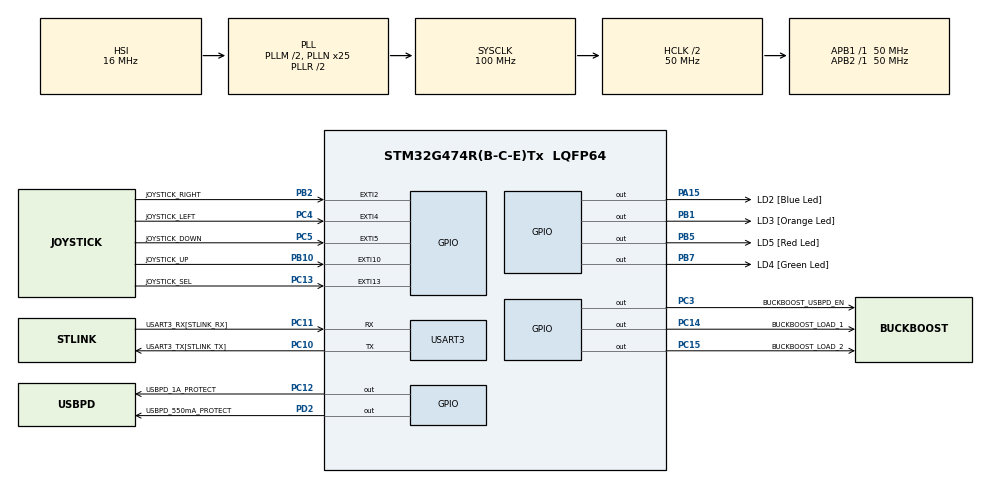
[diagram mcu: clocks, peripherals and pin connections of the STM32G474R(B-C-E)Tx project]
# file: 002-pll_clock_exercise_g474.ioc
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Mcu.Family=STM32G4
Mcu.Name=STM32G474R(B-C-E)Tx
Mcu.Package=LQFP64
NVIC.EXTI15_10_IRQn=true\:0\:0\:false\:false\:true\:true\:true
NVIC.EXTI2_IRQn=true\:0\:0\:false\:false\:true\:true\:true
NVIC.EXTI4_IRQn=true\:0\:0\:false\:false\:true\:true\:true
NVIC.EXTI9_5_IRQn=true\:0\:0\:false\:false\:true\:true\:true
NVIC.PriorityGroup=NVIC_PRIORITYGROUP_4
NVIC.USART3_IRQn=true\:0\:0\:false\:false\:true\:true\:true
PA0.GPIO_Label=BUCK_GREEN_SENSE
PA0.Signal=COMP3_INP
PA1.GPIO_Label=BUCKBOOST_VIN
PA1.Signal=ADC1_IN2
PA10.Signal=UCPD1_DBCC2
PA11.Signal=USB_DM
PA12.Signal=USB_DP
PA13.Mode=Serial_Wire
PA13.Signal=SYS_JTMS-SWDIO
PA14.Mode=Serial_Wire
PA14.Signal=SYS_JTCK-SWCLK
PA15.GPIO_Label=LD2 [Blue Led]
PA15.Signal=GPIO_Output
PA2.GPIO_Label=BUCKBOOST_I_IN_AVG
PA2.Signal=ADC1_IN3
PA3.GPIO_Label=BUCKBOOST_VOUT
PA3.Signal=ADC1_IN4
PA7.GPIO_Label=BUCK_RED_SENSE
PA7.Signal=COMP2_INP
PA8.GPIO_Label=BUCK_BLUE_DRIVE
PA8.Signal=HRTIM1_CHA1
PA9.Signal=UCPD1_DBCC1
PB0.GPIO_Label=BUCK_BLUE_SENSE
PB0.Signal=COMP4_INP
PB1.GPIO_Label=LD3 [Orange Led]
PB1.Signal=GPIO_Output
PB10.GPIO_Label=JOYSTICK_UP
PB10.GPIO_PuPd=GPIO_PULLUP
PB10.Signal=GPXTI10
PB11.GPIO_Label=BUCKBOOST_I_IN_SENSE
PB11.Signal=COMP6_INP
PB12.GPIO_Label=BUCKBOOST_P1_DRIVE
PB12.Signal=HRTIM1_CHC1
PB13.GPIO_Label=BUCKBOOST_N1_DRIVE
PB13.Signal=HRTIM1_CHC2
PB14.GPIO_Label=BUCKBOOST_N2_DRIVE
PB14.Signal=HRTIM1_CHD1
PB15.GPIO_Label=BUCKBOOST_P2_DRIVE
PB15.Signal=HRTIM1_CHD2
PB2.GPIO_Label=JOYSTICK_RIGHT
PB2.GPIO_PuPd=GPIO_PULLUP
PB2.Signal=GPXTI2
PB3.Signal=SYS_JTDO-SWO
PB4.Signal=UCPD1_CC2
PB5.GPIO_Label=LD5 [Red Led]
PB5.Signal=GPIO_Output
PB6.Signal=UCPD1_CC1
PB7.GPIO_Label=LD4 [Green Led]
PB7.Signal=GPIO_Output
PC10.GPIO_Label=USART3_TX[STLINK_TX]
PC10.GPIO_Speed=GPIO_SPEED_FREQ_MEDIUM
PC10.Mode=Asynchronous
PC10.Signal=USART3_TX
PC11.GPIO_Label=USART3_RX[STLINK_RX]
PC11.GPIO_Speed=GPIO_SPEED_FREQ_MEDIUM
PC11.Mode=Asynchronous
PC11.Signal=USART3_RX
PC12.GPIO_Label=USBPD_1A_PROTECT
PC12.Signal=GPIO_Output
PC13.GPIO_Label=JOYSTICK_SEL
PC13.GPIO_PuPd=GPIO_PULLUP
PC13.Signal=GPXTI13
PC14-OSC32_IN.GPIO_Label=BUCKBOOST_LOAD_1
PC14-OSC32_IN.Signal=GPIO_Output
PC15-OSC32_OUT.GPIO_Label=BUCKBOOST_LOAD_2
PC15-OSC32_OUT.Signal=GPIO_Output
PC2.GPIO_Label=USBPD_VIN
PC2.Signal=ADC1_IN8
PC3.GPIO_Label=BUCKBOOST_USBPD_EN
PC3.Signal=GPIO_Output
PC4.GPIO_Label=JOYSTICK_LEFT
PC4.GPIO_PuPd=GPIO_PULLUP
PC4.Signal=GPXTI4
PC5.GPIO_Label=JOYSTICK_DOWN
PC5.GPIO_PuPd=GPIO_PULLUP
PC5.Signal=GPXTI5
PC6.GPIO_Label=BUCK_RED_DRIVE
PC6.Signal=HRTIM1_CHF1
PC7.GPIO_Label=RC_TP4
PC7.Signal=HRTIM1_CHF2
PC8.GPIO_Label=BUCK_GREEN_DRIVE
PC8.Signal=HRTIM1_CHE1
PD2.GPIO_Label=USBPD_550mA_PROTECT
PD2.Signal=GPIO_Output
PF0-OSC_IN.Mode=HSE-External-Clock-Source
PF0-OSC_IN.Signal=RCC_OSC_IN
ProjectManager.HeapSize=0x200
ProjectManager.StackSize=0x400
ProjectManager.TargetToolchain=STM32CubeIDE
RCC.ADC12Freq_Value=100000000
RCC.ADC345Freq_Value=100000000
RCC.AHBCLKDivider=RCC_SYSCLK_DIV2
RCC.AHBFreq_Value=50000000
RCC.APB1Freq_Value=50000000
RCC.APB1TimFreq_Value=50000000
RCC.APB2Freq_Value=50000000
RCC.APB2TimFreq_Value=50000000
RCC.CK48CLockSelection=RCC_USBCLKSOURCE_HSI48
RCC.CortexFreq_Value=50000000
RCC.EXTERNAL_CLOCK_VALUE=12288000
RCC.HCLKFreq_Value=50000000
RCC.HSE_VALUE=8000000
RCC.HSI48_VALUE=48000000
RCC.HSI_VALUE=16000000
RCC.LSE_VALUE=32768
RCC.PLLM=RCC_PLLM_DIV2
RCC.PLLN=25
RCC.PLLP=RCC_PLLP_DIV8
RCC.PLLQ=RCC_PLLQ_DIV8
RCC.SYSCLKFreq_VALUE=100000000
RCC.SYSCLKSource=RCC_SYSCLKSOURCE_PLLCLK
RCC.USBFreq_Value=48000000
RCC.VCOOutputFreq_Value=200000000
USART3.VirtualMode-Asynchronous=VM_ASYNC
VP_SYS_VS_DBSignals.Mode=DisableDeadBatterySignals
board=B-G474E-DPOW1

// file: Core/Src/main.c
/* USER CODE BEGIN Header */
/**
  ******************************************************************************
  * @file           : main.c
  * @brief          : Main program body
  ******************************************************************************
  * @attention
  *
  * <h2><center>&copy; Copyright (c) 2020 STMicroelectronics.
  * All rights reserved.</center></h2>
  *
  * This software component is licensed by ST under BSD 3-Clause license,
  * the "License"; You may not use this file except in compliance with the
  * License. You may obtain a copy of the License at:
  *                        opensource.org/licenses/BSD-3-Clause
  *
  ******************************************************************************
  */
/* USER CODE END Header */

#include "main.h"
#include <stdio.h>
#include <string.h>

UART_HandleTypeDef huart3;

void SystemClock_Config(void);
static void MX_GPIO_Init(void);
static void MX_USART3_UART_Init(void);

int main(void)
{
  /* USER CODE BEGIN 1 */
	char msg[30] = {0};

  /* USER CODE END 1 */

  /* MCU Configuration--------------------------------------------------------*/

  /* Reset of all peripherals, Initializes the Flash interface and the Systick. */
  HAL_Init();

  /* Configure the system clock */
  SystemClock_Config();

  /* Initialize all configured peripherals */
  MX_GPIO_Init();
  MX_USART3_UART_Init();
  /* USER CODE BEGIN 2 */
  memset(msg, 0, sizeof(msg));
  sprintf(msg, "SYSCLK w/ PLL: %ld", HAL_RCC_GetSysClockFreq());
  HAL_UART_Transmit(&huart3, (uint8_t*)msg, strlen(msg), HAL_MAX_DELAY);

  /* USER CODE END 2 */

  /* Infinite loop */
  while (1)
  {

  }
}

void SystemClock_Config(void)
{
  RCC_OscInitTypeDef RCC_OscInitStruct = {0};
  RCC_ClkInitTypeDef RCC_ClkInitStruct = {0};
  RCC_PeriphCLKInitTypeDef PeriphClkInit = {0};

  /** Configure the main internal regulator output voltage
  */
  HAL_PWREx_ControlVoltageScaling(PWR_REGULATOR_VOLTAGE_SCALE1);
  /** Initializes the CPU, AHB and APB busses clocks
  */
  RCC_OscInitStruct.OscillatorType = RCC_OSCILLATORTYPE_HSI;
  RCC_OscInitStruct.HSIState = RCC_HSI_ON;
  RCC_OscInitStruct.HSICalibrationValue = RCC_HSICALIBRATION_DEFAULT;
  RCC_OscInitStruct.PLL.PLLState = RCC_PLL_ON;
  RCC_OscInitStruct.PLL.PLLSource = RCC_PLLSOURCE_HSI;
  RCC_OscInitStruct.PLL.PLLM = RCC_PLLM_DIV2;
  RCC_OscInitStruct.PLL.PLLN = 25;
  RCC_OscInitStruct.PLL.PLLP = RCC_PLLP_DIV8;
  RCC_OscInitStruct.PLL.PLLQ = RCC_PLLQ_DIV8;
  RCC_OscInitStruct.PLL.PLLR = RCC_PLLR_DIV2;
  if (HAL_RCC_OscConfig(&RCC_OscInitStruct) != HAL_OK)
  {
    Error_Handler();
  }
  /** Initializes the CPU, AHB and APB busses clocks
  */
  RCC_ClkInitStruct.ClockType = RCC_CLOCKTYPE_HCLK|RCC_CLOCKTYPE_SYSCLK
                              |RCC_CLOCKTYPE_PCLK1|RCC_CLOCKTYPE_PCLK2;
  RCC_ClkInitStruct.SYSCLKSource = RCC_SYSCLKSOURCE_PLLCLK;
  RCC_ClkInitStruct.AHBCLKDivider = RCC_SYSCLK_DIV2;
  RCC_ClkInitStruct.APB1CLKDivider = RCC_HCLK_DIV1;
  RCC_ClkInitStruct.APB2CLKDivider = RCC_HCLK_DIV1;

  if (HAL_RCC_ClockConfig(&RCC_ClkInitStruct, FLASH_LATENCY_2) != HAL_OK)
  {
    Error_Handler();
  }
  /** Initializes the peripherals clocks
  */
  PeriphClkInit.PeriphClockSelection = RCC_PERIPHCLK_USART3;
  PeriphClkInit.Usart3ClockSelection = RCC_USART3CLKSOURCE_PCLK1;
  if (HAL_RCCEx_PeriphCLKConfig(&PeriphClkInit) != HAL_OK)
  {
    Error_Handler();
  }
}

static void MX_USART3_UART_Init(void)
{

  huart3.Instance = USART3;
  huart3.Init.BaudRate = 115200;
  huart3.Init.WordLength = UART_WORDLENGTH_8B;
  huart3.Init.StopBits = UART_STOPBITS_1;
  huart3.Init.Parity = UART_PARITY_NONE;
  huart3.Init.Mode = UART_MODE_TX_RX;
  huart3.Init.HwFlowCtl = UART_HWCONTROL_NONE;
  huart3.Init.OverSampling = UART_OVERSAMPLING_16;
  huart3.Init.OneBitSampling = UART_ONE_BIT_SAMPLE_DISABLE;
  huart3.Init.ClockPrescaler = UART_PRESCALER_DIV1;
  huart3.AdvancedInit.AdvFeatureInit = UART_ADVFEATURE_NO_INIT;
  if (HAL_UART_Init(&huart3) != HAL_OK)
  {
    Error_Handler();
  }
  if (HAL_UARTEx_SetTxFifoThreshold(&huart3, UART_TXFIFO_THRESHOLD_1_8) != HAL_OK)
  {
    Error_Handler();
  }
  if (HAL_UARTEx_SetRxFifoThreshold(&huart3, UART_RXFIFO_THRESHOLD_1_8) != HAL_OK)
  {
    Error_Handler();
  }
  if (HAL_UARTEx_DisableFifoMode(&huart3) != HAL_OK)
  {
    Error_Handler();
  }

}

static void MX_GPIO_Init(void)
{
  GPIO_InitTypeDef GPIO_InitStruct = {0};

  /* GPIO Ports Clock Enable */
  __HAL_RCC_GPIOC_CLK_ENABLE();
  __HAL_RCC_GPIOF_CLK_ENABLE();
  __HAL_RCC_GPIOA_CLK_ENABLE();
  __HAL_RCC_GPIOB_CLK_ENABLE();
  __HAL_RCC_GPIOD_CLK_ENABLE();

  /*Configure GPIO pin Output Level */
  HAL_GPIO_WritePin(GPIOC, BUCKBOOST_LOAD_1_Pin|BUCKBOOST_LOAD_2_Pin|BUCKBOOST_USBPD_EN_Pin|USBPD_1A_PROTECT_Pin, GPIO_PIN_RESET);

  /*Configure GPIO pin Output Level */
  HAL_GPIO_WritePin(GPIOB, LD3_Pin|LD5_Pin|LD4_Pin, GPIO_PIN_RESET);

  /*Configure GPIO pin Output Level */
  HAL_GPIO_WritePin(LD2_GPIO_Port, LD2_Pin, GPIO_PIN_RESET);

  /*Configure GPIO pin Output Level */
  HAL_GPIO_WritePin(USBPD_550mA_PROTECT_GPIO_Port, USBPD_550mA_PROTECT_Pin, GPIO_PIN_RESET);

  /*Configure GPIO pins : JOYSTICK_SEL_Pin JOYSTICK_LEFT_Pin JOYSTICK_DOWN_Pin */
  GPIO_InitStruct.Pin = JOYSTICK_SEL_Pin|JOYSTICK_LEFT_Pin|JOYSTICK_DOWN_Pin;
  GPIO_InitStruct.Mode = GPIO_MODE_IT_RISING;
  GPIO_InitStruct.Pull = GPIO_PULLUP;
  HAL_GPIO_Init(GPIOC, &GPIO_InitStruct);

  /*Configure GPIO pins : BUCKBOOST_LOAD_1_Pin BUCKBOOST_LOAD_2_Pin BUCKBOOST_USBPD_EN_Pin USBPD_1A_PROTECT_Pin */
  GPIO_InitStruct.Pin = BUCKBOOST_LOAD_1_Pin|BUCKBOOST_LOAD_2_Pin|BUCKBOOST_USBPD_EN_Pin|USBPD_1A_PROTECT_Pin;
  GPIO_InitStruct.Mode = GPIO_MODE_OUTPUT_PP;
  GPIO_InitStruct.Pull = GPIO_NOPULL;
  GPIO_InitStruct.Speed = GPIO_SPEED_FREQ_LOW;
  HAL_GPIO_Init(GPIOC, &GPIO_InitStruct);

  /*Configure GPIO pin : USBPD_VIN_Pin */
  GPIO_InitStruct.Pin = USBPD_VIN_Pin;
  GPIO_InitStruct.Mode = GPIO_MODE_ANALOG;
  GPIO_InitStruct.Pull = GPIO_NOPULL;
  HAL_GPIO_Init(USBPD_VIN_GPIO_Port, &GPIO_InitStruct);

  /*Configure GPIO pins : BUCK_GREEN_SENSE_Pin BUCKBOOST_VIN_Pin BUCKBOOST_I_IN_AVG_Pin BUCKBOOST_VOUT_Pin
                           BUCK_RED_SENSE_Pin */
  GPIO_InitStruct.Pin = BUCK_GREEN_SENSE_Pin|BUCKBOOST_VIN_Pin|BUCKBOOST_I_IN_AVG_Pin|BUCKBOOST_VOUT_Pin
                          |BUCK_RED_SENSE_Pin;
  GPIO_InitStruct.Mode = GPIO_MODE_ANALOG;
  GPIO_InitStruct.Pull = GPIO_NOPULL;
  HAL_GPIO_Init(GPIOA, &GPIO_InitStruct);

  /*Configure GPIO pins : BUCK_BLUE_SENSE_Pin BUCKBOOST_I_IN_SENSE_Pin */
  GPIO_InitStruct.Pin = BUCK_BLUE_SENSE_Pin|BUCKBOOST_I_IN_SENSE_Pin;
  GPIO_InitStruct.Mode = GPIO_MODE_ANALOG;
  GPIO_InitStruct.Pull = GPIO_NOPULL;
  HAL_GPIO_Init(GPIOB, &GPIO_InitStruct);

  /*Configure GPIO pins : LD3_Pin LD5_Pin LD4_Pin */
  GPIO_InitStruct.Pin = LD3_Pin|LD5_Pin|LD4_Pin;
  GPIO_InitStruct.Mode = GPIO_MODE_OUTPUT_PP;
  GPIO_InitStruct.Pull = GPIO_NOPULL;
  GPIO_InitStruct.Speed = GPIO_SPEED_FREQ_LOW;
  HAL_GPIO_Init(GPIOB, &GPIO_InitStruct);

  /*Configure GPIO pins : JOYSTICK_RIGHT_Pin JOYSTICK_UP_Pin */
  GPIO_InitStruct.Pin = JOYSTICK_RIGHT_Pin|JOYSTICK_UP_Pin;
  GPIO_InitStruct.Mode = GPIO_MODE_IT_RISING;
  GPIO_InitStruct.Pull = GPIO_PULLUP;
  HAL_GPIO_Init(GPIOB, &GPIO_InitStruct);

  /*Configure GPIO pins : BUCKBOOST_P1_DRIVE_Pin BUCKBOOST_N1_DRIVE_Pin BUCKBOOST_N2_DRIVE_Pin BUCKBOOST_P2_DRIVE_Pin */
  GPIO_InitStruct.Pin = BUCKBOOST_P1_DRIVE_Pin|BUCKBOOST_N1_DRIVE_Pin|BUCKBOOST_N2_DRIVE_Pin|BUCKBOOST_P2_DRIVE_Pin;
  GPIO_InitStruct.Mode = GPIO_MODE_AF_PP;
  GPIO_InitStruct.Pull = GPIO_NOPULL;
  GPIO_InitStruct.Speed = GPIO_SPEED_FREQ_VERY_HIGH;
  GPIO_InitStruct.Alternate = GPIO_AF13_HRTIM1;
  HAL_GPIO_Init(GPIOB, &GPIO_InitStruct);

  /*Configure GPIO pins : BUCK_RED_DRIVE_Pin RC_TP4_Pin */
  GPIO_InitStruct.Pin = BUCK_RED_DRIVE_Pin|RC_TP4_Pin;
  GPIO_InitStruct.Mode = GPIO_MODE_AF_PP;
  GPIO_InitStruct.Pull = GPIO_NOPULL;
  GPIO_InitStruct.Speed = GPIO_SPEED_FREQ_VERY_HIGH;
  GPIO_InitStruct.Alternate = GPIO_AF13_HRTIM1;
  HAL_GPIO_Init(GPIOC, &GPIO_InitStruct);

  /*Configure GPIO pin : BUCK_GREEN_DRIVE_Pin */
  GPIO_InitStruct.Pin = BUCK_GREEN_DRIVE_Pin;
  GPIO_InitStruct.Mode = GPIO_MODE_AF_PP;
  GPIO_InitStruct.Pull = GPIO_NOPULL;
  GPIO_InitStruct.Speed = GPIO_SPEED_FREQ_VERY_HIGH;
  GPIO_InitStruct.Alternate = GPIO_AF3_HRTIM1;
  HAL_GPIO_Init(BUCK_GREEN_DRIVE_GPIO_Port, &GPIO_InitStruct);

  /*Configure GPIO pin : BUCK_BLUE_DRIVE_Pin */
  GPIO_InitStruct.Pin = BUCK_BLUE_DRIVE_Pin;
  GPIO_InitStruct.Mode = GPIO_MODE_AF_PP;
  GPIO_InitStruct.Pull = GPIO_NOPULL;
  GPIO_InitStruct.Speed = GPIO_SPEED_FREQ_VERY_HIGH;
  GPIO_InitStruct.Alternate = GPIO_AF13_HRTIM1;
  HAL_GPIO_Init(BUCK_BLUE_DRIVE_GPIO_Port, &GPIO_InitStruct);

  /*Configure GPIO pin : LD2_Pin */
  GPIO_InitStruct.Pin = LD2_Pin;
  GPIO_InitStruct.Mode = GPIO_MODE_OUTPUT_PP;
  GPIO_InitStruct.Pull = GPIO_NOPULL;
  GPIO_InitStruct.Speed = GPIO_SPEED_FREQ_LOW;
  HAL_GPIO_Init(LD2_GPIO_Port, &GPIO_InitStruct);

  /*Configure GPIO pin : USBPD_550mA_PROTECT_Pin */
  GPIO_InitStruct.Pin = USBPD_550mA_PROTECT_Pin;
  GPIO_InitStruct.Mode = GPIO_MODE_OUTPUT_PP;
  GPIO_InitStruct.Pull = GPIO_NOPULL;
  GPIO_InitStruct.Speed = GPIO_SPEED_FREQ_LOW;
  HAL_GPIO_Init(USBPD_550mA_PROTECT_GPIO_Port, &GPIO_InitStruct);

  /* EXTI interrupt init*/
  HAL_NVIC_SetPriority(EXTI2_IRQn, 0, 0);
  HAL_NVIC_EnableIRQ(EXTI2_IRQn);

  HAL_NVIC_SetPriority(EXTI4_IRQn, 0, 0);
  HAL_NVIC_EnableIRQ(EXTI4_IRQn);

  HAL_NVIC_SetPriority(EXTI9_5_IRQn, 0, 0);
  HAL_NVIC_EnableIRQ(EXTI9_5_IRQn);

  HAL_NVIC_SetPriority(EXTI15_10_IRQn, 0, 0);
  HAL_NVIC_EnableIRQ(EXTI15_10_IRQn);

}

void Error_Handler(void)
{
}

/************************ (C) COPYRIGHT STMicroelectronics *****END OF FILE****/
